AUTOSAR XML (schema 314)
package /ComponentType
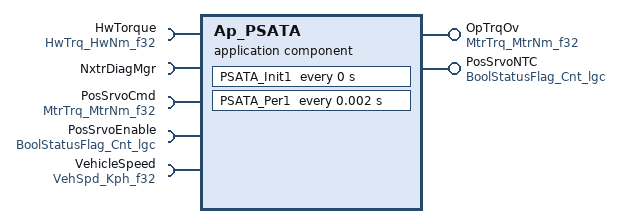
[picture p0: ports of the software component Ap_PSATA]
  application software component type Ap_PSATA
    provide port OpTrqOv: unqueued-sender-com-spec{data-element=MtrNm_f32, can-invalidate=false, init-value=D_ZERO_ULS_F32}, provided-interface=MtrTrq_MtrNm_f32
    provide port PosSrvoNTC: unqueued-sender-com-spec{data-element=Cnt_lgc, can-invalidate=false, init-value=D_FALSE_CNT_LGC}, provided-interface=BoolStatusFlag_Cnt_lgc
    5 x require port:
      HwTorque: unqueued-receiver-com-spec{data-element=HwNm_f32, init-value=D_ZERO_ULS_F32}, required-interface=HwTrq_HwNm_f32
      NxtrDiagMgr: required-com-specs=[GetNTCActive, GetNTCFailed, GetNTCStatus, SetNTCStatus], required-interface=NxtrDiagMgr
      PosSrvoCmd: unqueued-receiver-com-spec{data-element=MtrNm_f32, init-value=D_ZERO_ULS_F32}, required-interface=MtrTrq_MtrNm_f32
      PosSrvoEnable: unqueued-receiver-com-spec{data-element=Cnt_lgc, init-value=D_FALSE_CNT_LGC}, required-interface=BoolStatusFlag_Cnt_lgc
      VehicleSpeed: unqueued-receiver-com-spec{data-element=Kph_f32, init-value=D_ZERO_ULS_F32}, required-interface=VehSpd_Kph_f32
  internal behavior Ap_PSATA_InternalBehavior: component=Ap_PSATA
    timing event PSATA_Init1_InitEvent: start-on-event=PSATA_Init1, period=0
    timing event TMT_PSATA_Per1: start-on-event=PSATA_Per1, period=0.002
    port-api-options:
      enable-take-address=false, indirect-api=false, port=HwTorque
      enable-take-address=false, indirect-api=false, port=NxtrDiagMgr
      enable-take-address=false, indirect-api=false, port=OpTrqOv
      enable-take-address=false, indirect-api=false, port=PosSrvoCmd
      enable-take-address=false, indirect-api=false, port=PosSrvoEnable
      enable-take-address=false, indirect-api=false, port=PosSrvoNTC
      enable-take-address=false, indirect-api=false, port=VehicleSpeed
    runnable PSATA_Init1
    runnable PSATA_Per1
      4 x data read access:
        READ_HwTorque_HwNm_f32: data-element=HwTorque.HwNm_f32
        READ_PosSrvoCmd_MtrNm_f32: data-element=PosSrvoCmd.MtrNm_f32
        READ_PosSrvoEnable_Cnt_lgc: data-element=PosSrvoEnable.Cnt_lgc
        READ_VehicleSpeed_Kph_f32: data-element=VehicleSpeed.Kph_f32
      data write access WRITE_OpTrqOv_MtrNm_f32: data-element=OpTrqOv.MtrNm_f32
      data write access WRITE_PosSrvoNTC_Cnt_lgc: data-element=PosSrvoNTC.Cnt_lgc
      sync call SC_NxtrDiagMgr_SetNTCStatus: operation=NxtrDiagMgr.SetNTCStatus, timeout=0
  swc implementation Ap_PSATA_Implementation: behavior=Ap_PSATA_InternalBehavior
    code-descriptors:
      code Code: type=SRC
